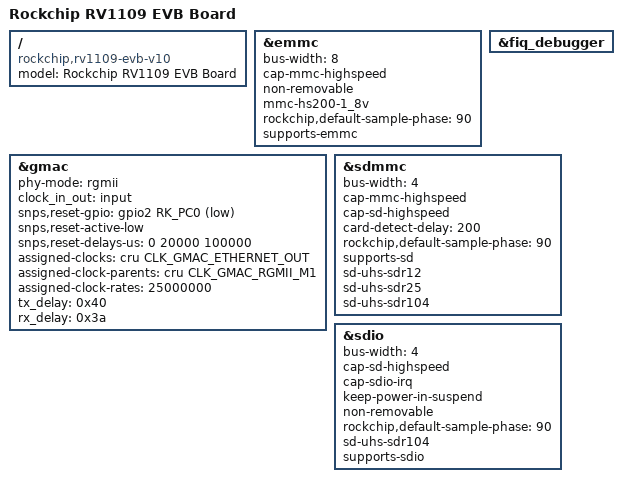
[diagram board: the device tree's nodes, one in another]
// SPDX-License-Identifier: (GPL-2.0+ OR MIT)
/*
 * Copyright (c) 2019 Fuzhou Rockchip Electronics Co., Ltd.
 */

/dts-v1/;

#include "rv1109.dtsi"

/ {
	model = "Rockchip RV1109 EVB Board";
	compatible = "rockchip,rv1109-evb-v10", "rockchip,rv1109";
};

&emmc {
	bus-width = <8>;
	cap-mmc-highspeed;
	non-removable;
	mmc-hs200-1_8v;
	rockchip,default-sample-phase = <90>;
	supports-emmc;
	status = "okay";
};

&fiq_debugger {
	status = "okay";
};

&gmac {
	phy-mode = "rgmii";
	clock_in_out = "input";
	snps,reset-gpio = <&gpio2 RK_PC0 GPIO_ACTIVE_LOW>;
	snps,reset-active-low;
	/* Reset time is 20ms, 100ms for rtl8211f */
	snps,reset-delays-us = <0 20000 100000>;
	assigned-clocks = <&cru CLK_GMAC_SRC>;
	assigned-clock-parents = <&cru CLK_GMAC_RGMII_M1>;
	assigned-clocks = <&cru CLK_GMAC_ETHERNET_OUT>;
	assigned-clock-rates = <25000000>;
	tx_delay = <0x40>;
	rx_delay = <0x3a>;
	status = "okay";
};

&sdmmc {
	bus-width = <4>;
	cap-mmc-highspeed;
	cap-sd-highspeed;
	card-detect-delay = <200>;
	rockchip,default-sample-phase = <90>;
	supports-sd;
	sd-uhs-sdr12;
	sd-uhs-sdr25;
	sd-uhs-sdr104;
	status = "okay";
};

&sdio {
	bus-width = <4>;
	cap-sd-highspeed;
	cap-sdio-irq;
	keep-power-in-suspend;
	non-removable;
	rockchip,default-sample-phase = <90>;
	sd-uhs-sdr104;
	supports-sdio;
	status = "okay";
};
